VERSION ""

NS_ :

BS_:

BU_: ROS RAPTOR INV

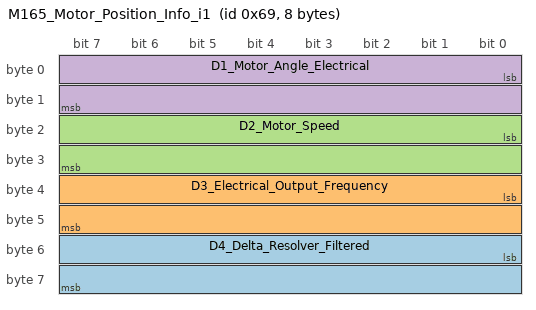
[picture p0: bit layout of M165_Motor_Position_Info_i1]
BO_ 105 M165_Motor_Position_Info_i1: 8 INV
 SG_ D4_Delta_Resolver_Filtered : 48|16@1- (0.1,0) [-3276.8|3276.7] "deg" Vector__XXX
 SG_ D3_Electrical_Output_Frequency : 32|16@1- (0.1,0) [-3276.8|3276.7] "hz" Vector__XXX
 SG_ D2_Motor_Speed : 16|16@1- (1,0) [-32768|32767] "rpm" Vector__XXX
 SG_ D1_Motor_Angle_Electrical : 0|16@1+ (0.1,0) [0|6553.5] "deg" Vector__XXX
